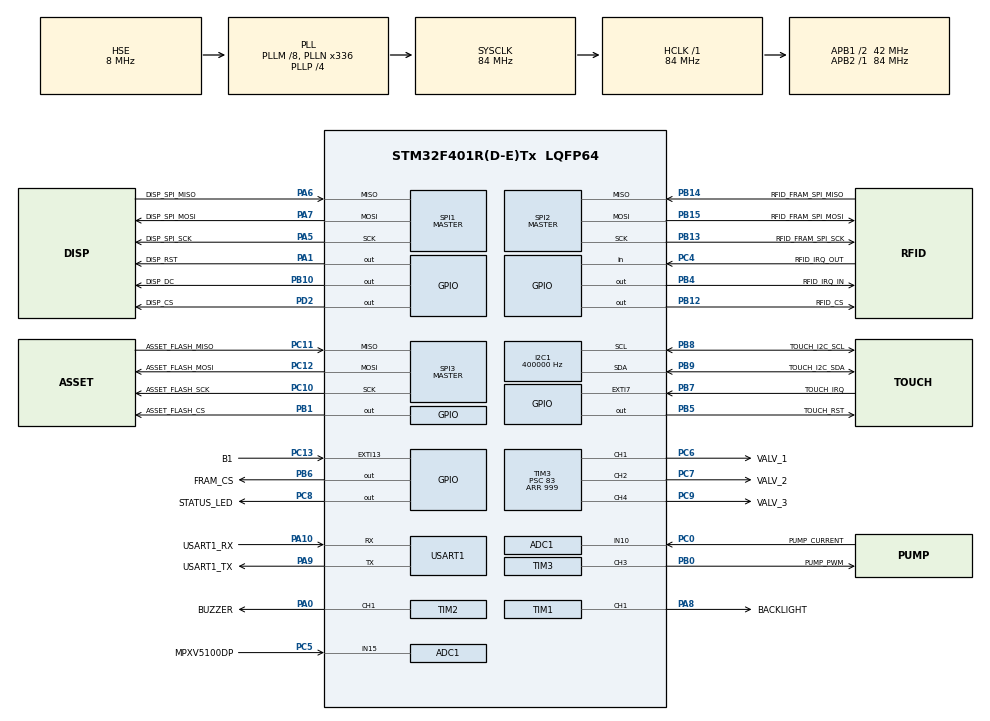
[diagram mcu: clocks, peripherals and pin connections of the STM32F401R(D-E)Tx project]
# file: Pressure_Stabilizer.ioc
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ADC1.Channel-0\#ChannelRegularConversion=ADC_CHANNEL_15
ADC1.Channel-1\#ChannelRegularConversion=ADC_CHANNEL_10
ADC1.NbrOfConversionFlag=2
ADC1.Rank-0\#ChannelRegularConversion=1
ADC1.Rank-1\#ChannelRegularConversion=2
ADC1.SamplingTime-0\#ChannelRegularConversion=ADC_SAMPLETIME_84CYCLES
ADC1.SamplingTime-1\#ChannelRegularConversion=ADC_SAMPLETIME_84CYCLES
ADC1.master=1
Dma.Request0=SPI1_TX
Dma.Request1=SPI3_RX
Dma.Request2=SPI3_TX
Dma.SPI1_TX.0.Direction=DMA_MEMORY_TO_PERIPH
Dma.SPI1_TX.0.FIFOMode=DMA_FIFOMODE_DISABLE
Dma.SPI1_TX.0.Instance=DMA2_Stream3
Dma.SPI1_TX.0.MemDataAlignment=DMA_MDATAALIGN_BYTE
Dma.SPI1_TX.0.MemInc=DMA_MINC_ENABLE
Dma.SPI1_TX.0.Mode=DMA_NORMAL
Dma.SPI1_TX.0.PeriphDataAlignment=DMA_PDATAALIGN_BYTE
Dma.SPI1_TX.0.PeriphInc=DMA_PINC_DISABLE
Dma.SPI1_TX.0.Priority=DMA_PRIORITY_HIGH
Dma.SPI3_RX.1.Direction=DMA_PERIPH_TO_MEMORY
Dma.SPI3_RX.1.FIFOMode=DMA_FIFOMODE_DISABLE
Dma.SPI3_RX.1.Instance=DMA1_Stream0
Dma.SPI3_RX.1.MemDataAlignment=DMA_MDATAALIGN_BYTE
Dma.SPI3_RX.1.MemInc=DMA_MINC_ENABLE
Dma.SPI3_RX.1.Mode=DMA_NORMAL
Dma.SPI3_RX.1.PeriphDataAlignment=DMA_PDATAALIGN_BYTE
Dma.SPI3_RX.1.PeriphInc=DMA_PINC_DISABLE
Dma.SPI3_RX.1.Priority=DMA_PRIORITY_HIGH
Dma.SPI3_TX.2.Direction=DMA_MEMORY_TO_PERIPH
Dma.SPI3_TX.2.FIFOMode=DMA_FIFOMODE_DISABLE
Dma.SPI3_TX.2.Instance=DMA1_Stream5
Dma.SPI3_TX.2.MemDataAlignment=DMA_MDATAALIGN_BYTE
Dma.SPI3_TX.2.MemInc=DMA_MINC_ENABLE
Dma.SPI3_TX.2.Mode=DMA_NORMAL
Dma.SPI3_TX.2.PeriphDataAlignment=DMA_PDATAALIGN_BYTE
Dma.SPI3_TX.2.PeriphInc=DMA_PINC_DISABLE
Dma.SPI3_TX.2.Priority=DMA_PRIORITY_HIGH
I2C1.ClockSpeed=400000
Mcu.Family=STM32F4
Mcu.Name=STM32F401R(D-E)Tx
Mcu.Package=LQFP64
NVIC.DMA1_Stream0_IRQn=true\:1\:0\:false\:false\:true\:true\:true\:true
NVIC.DMA1_Stream5_IRQn=true\:1\:0\:false\:false\:true\:true\:true\:true
NVIC.DMA2_Stream3_IRQn=true\:0\:0\:false\:false\:true\:true\:true\:true
NVIC.EXTI9_5_IRQn=true\:1\:0\:false\:false\:true\:true\:true\:true
NVIC.PriorityGroup=NVIC_PRIORITYGROUP_4
NVIC.TIM1_TRG_COM_TIM11_IRQn=true\:0\:0\:false\:false\:true\:true\:true\:true
NVIC.USART1_IRQn=true\:0\:0\:false\:false\:true\:true\:true\:true
PA0-WKUP.GPIO_Label=BUZZER
PA0-WKUP.Signal=S_TIM2_CH1_ETR
PA1.GPIO_Label=DISP_RST
PA1.Signal=GPIO_Output
PA10.GPIO_Label=USART1_RX
PA10.GPIO_Mode=GPIO_MODE_AF_PP
PA10.GPIO_PuPd=GPIO_NOPULL
PA10.GPIO_Speed=GPIO_SPEED_FREQ_VERY_HIGH
PA10.Mode=Asynchronous
PA10.Signal=USART1_RX
PA13.GPIO_Label=TMS
PA13.Mode=Serial_Wire
PA13.Signal=SYS_JTMS-SWDIO
PA14.GPIO_Label=TCK
PA14.Mode=Serial_Wire
PA14.Signal=SYS_JTCK-SWCLK
PA5.GPIO_Label=DISP_SPI_SCK
PA5.Mode=Full_Duplex_Master
PA5.Signal=SPI1_SCK
PA6.GPIO_Label=DISP_SPI_MISO
PA6.Mode=Full_Duplex_Master
PA6.Signal=SPI1_MISO
PA7.GPIO_Label=DISP_SPI_MOSI
PA7.Mode=Full_Duplex_Master
PA7.Signal=SPI1_MOSI
PA8.GPIO_Label=BACKLIGHT
PA8.Signal=S_TIM1_CH1
PA9.GPIO_Label=USART1_TX
PA9.GPIO_Mode=GPIO_MODE_AF_PP
PA9.GPIO_PuPd=GPIO_NOPULL
PA9.GPIO_Speed=GPIO_SPEED_FREQ_VERY_HIGH
PA9.Mode=Asynchronous
PA9.Signal=USART1_TX
PB0.GPIO_Label=PUMP_PWM
PB0.Signal=S_TIM3_CH3
PB1.GPIO_Label=ASSET_FLASH_CS
PB1.GPIO_Speed=GPIO_SPEED_FREQ_VERY_HIGH
PB1.PinState=GPIO_PIN_SET
PB1.Signal=GPIO_Output
PB10.GPIO_Label=DISP_DC
PB10.Signal=GPIO_Output
PB12.GPIO_Label=RFID_CS
PB12.Signal=GPIO_Output
PB13.GPIO_Label=RFID_FRAM_SPI_SCK
PB13.Mode=Full_Duplex_Master
PB13.Signal=SPI2_SCK
PB14.GPIO_Label=RFID_FRAM_SPI_MISO
PB14.Mode=Full_Duplex_Master
PB14.Signal=SPI2_MISO
PB15.GPIO_Label=RFID_FRAM_SPI_MOSI
PB15.Mode=Full_Duplex_Master
PB15.Signal=SPI2_MOSI
PB4.GPIO_Label=RFID_IRQ_IN
PB4.Signal=GPIO_Output
PB5.GPIO_Label=TOUCH_RST
PB5.Signal=GPIO_Output
PB6.GPIO_Label=FRAM_CS
PB6.Signal=GPIO_Output
PB7.GPIO_Label=TOUCH_IRQ
PB7.GPIO_ModeDefaultEXTI=GPIO_MODE_IT_FALLING
PB7.GPIO_PuPd=GPIO_PULLUP
PB7.Signal=GPXTI7
PB8.GPIO_Label=TOUCH_I2C_SCL
PB8.Mode=I2C
PB8.Signal=I2C1_SCL
PB9.GPIO_Label=TOUCH_I2C_SDA
PB9.Mode=I2C
PB9.Signal=I2C1_SDA
PC0.GPIO_Label=PUMP_CURRENT
PC0.Signal=ADCx_IN10
PC13-ANTI_TAMP.GPIO_Label=B1
PC13-ANTI_TAMP.GPIO_ModeDefaultEXTI=GPIO_MODE_IT_FALLING
PC13-ANTI_TAMP.GPIO_PuPd=GPIO_NOPULL
PC13-ANTI_TAMP.Signal=GPXTI13
PC14-OSC32_IN.Mode=LSE-External-Oscillator
PC14-OSC32_IN.Signal=RCC_OSC32_IN
PC15-OSC32_OUT.Mode=LSE-External-Oscillator
PC15-OSC32_OUT.Signal=RCC_OSC32_OUT
PC4.GPIO_Label=RFID_IRQ_OUT
PC4.Signal=GPIO_Input
PC5.GPIO_Label=MPXV5100DP
PC5.Signal=ADCx_IN15
PC6.GPIO_Label=VALV_1
PC6.Signal=S_TIM3_CH1
PC7.GPIO_Label=VALV_2
PC7.Signal=S_TIM3_CH2
PC8.GPIO_Label=STATUS_LED
PC8.Signal=GPIO_Output
PC9.GPIO_Label=VALV_3
PC9.Signal=S_TIM3_CH4
PC10.GPIO_Label=ASSET_FLASH_SCK
PC10.GPIO_Speed=GPIO_SPEED_FREQ_VERY_HIGH
PC10.Mode=Full_Duplex_Master
PC10.Signal=SPI3_SCK
PC11.GPIO_Label=ASSET_FLASH_MISO
PC11.GPIO_Speed=GPIO_SPEED_FREQ_VERY_HIGH
PC11.Mode=Full_Duplex_Master
PC11.Signal=SPI3_MISO
PC12.GPIO_Label=ASSET_FLASH_MOSI
PC12.GPIO_Speed=GPIO_SPEED_FREQ_VERY_HIGH
PC12.Mode=Full_Duplex_Master
PC12.Signal=SPI3_MOSI
PD2.GPIO_Label=DISP_CS
PD2.GPIO_Speed=GPIO_SPEED_FREQ_VERY_HIGH
PD2.Signal=GPIO_Output
PH0\ -\ OSC_IN.Mode=HSE-External-Clock-Source
PH0\ -\ OSC_IN.Signal=RCC_OSC_IN
PH1\ -\ OSC_OUT.Mode=HSE-External-Clock-Source
PH1\ -\ OSC_OUT.Signal=RCC_OSC_OUT
ProjectManager.HeapSize=0x200
ProjectManager.StackSize=0x400
ProjectManager.TargetToolchain=STM32CubeIDE
RCC.48MHZClocksFreq_Value=48000000
RCC.AHBFreq_Value=84000000
RCC.APB1CLKDivider=RCC_HCLK_DIV2
RCC.APB1Freq_Value=42000000
RCC.APB1TimFreq_Value=84000000
RCC.APB2Freq_Value=84000000
RCC.APB2TimFreq_Value=84000000
RCC.CortexFreq_Value=84000000
RCC.HCLKFreq_Value=84000000
RCC.HSE_VALUE=8000000
RCC.HSI_VALUE=16000000
RCC.LSE_VALUE=32768
RCC.PLLM=8
RCC.PLLN=336
RCC.PLLP=RCC_PLLP_DIV4
RCC.PLLQ=7
RCC.PLLSourceVirtual=RCC_PLLSOURCE_HSE
RCC.SYSCLKFreq_VALUE=84000000
RCC.SYSCLKSource=RCC_SYSCLKSOURCE_PLLCLK
RCC.VCOOutputFreq_Value=336000000
SH.ADCx_IN10.0=ADC1_IN10,IN10
SH.ADCx_IN15.0=ADC1_IN15,IN15
SH.S_TIM2_CH1_ETR.0=TIM2_CH1,PWM Generation1 CH1
SH.S_TIM1_CH1.0=TIM1_CH1,PWM Generation1 CH1
SH.S_TIM3_CH1.0=TIM3_CH1,PWM Generation1 CH1
SH.S_TIM3_CH2.0=TIM3_CH2,PWM Generation2 CH2
SH.S_TIM3_CH3.0=TIM3_CH3,PWM Generation3 CH3
SH.S_TIM3_CH4.0=TIM3_CH4,PWM Generation4 CH4
SPI1.BaudRatePrescaler=SPI_BAUDRATEPRESCALER_16
SPI1.CRCCalculation=SPI_CRCCALCULATION_DISABLE
SPI1.Direction=SPI_DIRECTION_2LINES
SPI1.Mode=SPI_MODE_MASTER
SPI1.VirtualType=VM_MASTER
SPI2.BaudRatePrescaler=SPI_BAUDRATEPRESCALER_32
SPI2.CRCCalculation=SPI_CRCCALCULATION_DISABLE
SPI2.Direction=SPI_DIRECTION_2LINES
SPI2.Mode=SPI_MODE_MASTER
SPI2.VirtualType=VM_MASTER
SPI3.BaudRatePrescaler=SPI_BAUDRATEPRESCALER_2
SPI3.CRCCalculation=SPI_CRCCALCULATION_DISABLE
SPI3.Direction=SPI_DIRECTION_2LINES
SPI3.Mode=SPI_MODE_MASTER
SPI3.VirtualType=VM_MASTER
STMicroelectronics.X-CUBE-TOUCHGFX.4.26.0.ApplicationCcGraphicsJjApplication=TouchGFXOoGenerator
STMicroelectronics.X-CUBE-TOUCHGFX.4.26.0.tgfx_block_size=6400
STMicroelectronics.X-CUBE-TOUCHGFX.4.26.0.tgfx_buffering_strategy=Partial
STMicroelectronics.X-CUBE-TOUCHGFX.4.26.0.tgfx_custom_height=480
STMicroelectronics.X-CUBE-TOUCHGFX.4.26.0.tgfx_custom_width=320
STMicroelectronics.X-CUBE-TOUCHGFX.4.26.0.tgfx_datareader=Enabled
STMicroelectronics.X-CUBE-TOUCHGFX.4.26.0.tgfx_datareader_dma_transfersize=250
STMicroelectronics.X-CUBE-TOUCHGFX.4.26.0.tgfx_datareader_mem_base_address=0x90000000
STMicroelectronics.X-CUBE-TOUCHGFX.4.26.0.tgfx_number_of_blocks=2
STMicroelectronics.X-CUBE-TOUCHGFX.4.26.0_IsPackSelfContextualization=true
TIM11.Period=165
TIM11.Prescaler=8399
TIM1.Channel-PWM\ Generation1\ CH1=TIM_CHANNEL_1
TIM1.Period=4199
TIM1.Prescaler=0
TIM1.Pulse-PWM\ Generation1\ CH1=4199
TIM2.AutoReloadPreload=TIM_AUTORELOAD_PRELOAD_ENABLE
TIM2.Channel-PWM\ Generation1\ CH1=TIM_CHANNEL_1
TIM2.Period=55999
TIM2.Prescaler=0
TIM2.Pulse-PWM\ Generation1\ CH1=27999
TIM3.Channel-PWM\ Generation1\ CH1=TIM_CHANNEL_1
TIM3.Channel-PWM\ Generation2\ CH2=TIM_CHANNEL_2
TIM3.Channel-PWM\ Generation3\ CH3=TIM_CHANNEL_3
TIM3.Channel-PWM\ Generation4\ CH4=TIM_CHANNEL_4
TIM3.Period=999
TIM3.Prescaler=83
TIM3.Pulse-PWM\ Generation1\ CH1=0
TIM3.Pulse-PWM\ Generation2\ CH2=0
TIM3.Pulse-PWM\ Generation3\ CH3=0
TIM3.Pulse-PWM\ Generation4\ CH4=0
USART1.VirtualMode=VM_ASYNC
VP_CRC_VS_CRC.Mode=CRC_Activate
VP_STMicroelectronics.X-CUBE-TOUCHGFX_VS_GraphicsJjApplication_4.26.0.Mode=GraphicsJjApplication
VP_TIM11_VS_ClockSourceINT.Mode=Enable_Timer
VP_TIM3_VS_ClockSourceINT.Mode=Internal
board=NUCLEO-F401RE

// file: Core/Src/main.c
/* USER CODE BEGIN Header */
/**
  ******************************************************************************
  * @file           : main.c
  * @brief          : Main program body
  ******************************************************************************
  * @attention
  *
  * Copyright (c) 2026 STMicroelectronics.
  * All rights reserved.
  *
  * This software is licensed under terms that can be found in the LICENSE file
  * in the root directory of this software component.
  * If no LICENSE file comes with this software, it is provided AS-IS.
  *
  ******************************************************************************
  */
/* USER CODE END Header */
#include "main.h"
#include "app_touchgfx.h"

/* USER CODE BEGIN Includes */
#include "RVA15MD_DisplayDriver.h"
#include "application_runtime.h"
#include "bandy_session_store.h"
#include "display_backlight.h"
#include "shared_spi2.h"
#include "w25q128jv.h"
/* USER CODE END Includes */

ADC_HandleTypeDef hadc1;

CRC_HandleTypeDef hcrc;

I2C_HandleTypeDef hi2c1;

SPI_HandleTypeDef hspi1;
SPI_HandleTypeDef hspi2;
SPI_HandleTypeDef hspi3;

TIM_HandleTypeDef htim1;
TIM_HandleTypeDef htim2;
TIM_HandleTypeDef htim3;
TIM_HandleTypeDef htim11;

UART_HandleTypeDef huart1;

DMA_HandleTypeDef hdma_spi1_tx;
DMA_HandleTypeDef hdma_spi3_rx;
DMA_HandleTypeDef hdma_spi3_tx;

void SystemClock_Config(void);
static void MX_GPIO_Init(void);
static void MX_ADC1_Init(void);
static void MX_CRC_Init(void);
static void MX_I2C1_Init(void);
static void MX_SPI1_Init(void);
static void MX_SPI2_Init(void);
static void MX_SPI3_Init(void);
static void MX_TIM1_Init(void);
static void MX_TIM3_Init(void);
static void MX_TIM11_Init(void);
static void MX_USART1_UART_Init(void);
static void MX_TIM2_Init(void);
static void MX_DMA_Init(void);

int main(void)
{

  /* MCU Configuration--------------------------------------------------------*/

  /* Reset of all peripherals, Initializes the Flash interface and the Systick. */
  HAL_Init();

  /* Configure the system clock */
  SystemClock_Config();

  /* Initialize all configured peripherals */
  MX_GPIO_Init();
  MX_DMA_Init();
  MX_ADC1_Init();
  MX_CRC_Init();
  MX_I2C1_Init();
  MX_SPI1_Init();
  MX_SPI2_Init();
  MX_SPI3_Init();
  MX_TIM1_Init();
  MX_TIM3_Init();
  MX_TIM11_Init();
  MX_USART1_UART_Init();
  MX_TIM2_Init();
  MX_TouchGFX_Init();
  /* USER CODE BEGIN 2 */
  SharedSpi2_Init();
  BandySessionStore_Init();
  DisplayBacklight_Init(&htim1, TIM_CHANNEL_1);
  DisplayDriver_DisplayReset();
  DisplayDriver_Init();
  DisplayDriver_DisplayInit();
  DisplayDriver_DisplayOn();
  App_init();
  HAL_TIM_Base_Start_IT(&htim11);
  /* USER CODE END 2 */

  /* Infinite loop */
  /* USER CODE BEGIN WHILE */
  while (1)
  {
    App_process();
    /* USER CODE END WHILE */

  MX_TouchGFX_Process();
  }
}

void SystemClock_Config(void)
{
  RCC_OscInitTypeDef RCC_OscInitStruct = {0};
  RCC_ClkInitTypeDef RCC_ClkInitStruct = {0};

  /** Configure the main internal regulator output voltage
  */
  __HAL_RCC_PWR_CLK_ENABLE();
  __HAL_PWR_VOLTAGESCALING_CONFIG(PWR_REGULATOR_VOLTAGE_SCALE2);

  /** Initializes the RCC Oscillators according to the specified parameters
  * in the RCC_OscInitTypeDef structure.
  */
  RCC_OscInitStruct.OscillatorType = RCC_OSCILLATORTYPE_HSE|RCC_OSCILLATORTYPE_LSE;
  RCC_OscInitStruct.HSEState = RCC_HSE_BYPASS;
  RCC_OscInitStruct.LSEState = RCC_LSE_ON;
  RCC_OscInitStruct.PLL.PLLState = RCC_PLL_ON;
  RCC_OscInitStruct.PLL.PLLSource = RCC_PLLSOURCE_HSE;
  RCC_OscInitStruct.PLL.PLLM = 8;
  RCC_OscInitStruct.PLL.PLLN = 336;
  RCC_OscInitStruct.PLL.PLLP = RCC_PLLP_DIV4;
  RCC_OscInitStruct.PLL.PLLQ = 7;
  if (HAL_RCC_OscConfig(&RCC_OscInitStruct) != HAL_OK)
  {
    Error_Handler();
  }

  /** Initializes the CPU, AHB and APB buses clocks
  */
  RCC_ClkInitStruct.ClockType = RCC_CLOCKTYPE_HCLK|RCC_CLOCKTYPE_SYSCLK
                              |RCC_CLOCKTYPE_PCLK1|RCC_CLOCKTYPE_PCLK2;
  RCC_ClkInitStruct.SYSCLKSource = RCC_SYSCLKSOURCE_PLLCLK;
  RCC_ClkInitStruct.AHBCLKDivider = RCC_SYSCLK_DIV1;
  RCC_ClkInitStruct.APB1CLKDivider = RCC_HCLK_DIV2;
  RCC_ClkInitStruct.APB2CLKDivider = RCC_HCLK_DIV1;

  if (HAL_RCC_ClockConfig(&RCC_ClkInitStruct, FLASH_LATENCY_2) != HAL_OK)
  {
    Error_Handler();
  }
}

static void MX_ADC1_Init(void)
{

  ADC_ChannelConfTypeDef sConfig = {0};

  /** Configure the global features of the ADC (Clock, Resolution, Data Alignment and number of conversion)
  */
  hadc1.Instance = ADC1;
  hadc1.Init.ClockPrescaler = ADC_CLOCK_SYNC_PCLK_DIV4;
  hadc1.Init.Resolution = ADC_RESOLUTION_12B;
  hadc1.Init.ScanConvMode = DISABLE;
  hadc1.Init.ContinuousConvMode = DISABLE;
  hadc1.Init.DiscontinuousConvMode = DISABLE;
  hadc1.Init.ExternalTrigConvEdge = ADC_EXTERNALTRIGCONVEDGE_NONE;
  hadc1.Init.ExternalTrigConv = ADC_SOFTWARE_START;
  hadc1.Init.DataAlign = ADC_DATAALIGN_RIGHT;
  hadc1.Init.NbrOfConversion = 1;
  hadc1.Init.DMAContinuousRequests = DISABLE;
  hadc1.Init.EOCSelection = ADC_EOC_SINGLE_CONV;
  if (HAL_ADC_Init(&hadc1) != HAL_OK)
  {
    Error_Handler();
  }

  /** Configure for the selected ADC regular channel its corresponding rank in the sequencer and its sample time.
  */
  sConfig.Channel = ADC_CHANNEL_15;
  sConfig.Rank = 1;
  sConfig.SamplingTime = ADC_SAMPLETIME_84CYCLES;
  if (HAL_ADC_ConfigChannel(&hadc1, &sConfig) != HAL_OK)
  {
    Error_Handler();
  }

  /** Configure for the selected ADC regular channel its corresponding rank in the sequencer and its sample time.
  */
  sConfig.Channel = ADC_CHANNEL_10;
  sConfig.Rank = 2;
  if (HAL_ADC_ConfigChannel(&hadc1, &sConfig) != HAL_OK)
  {
    Error_Handler();
  }

}

static void MX_CRC_Init(void)
{

  hcrc.Instance = CRC;
  if (HAL_CRC_Init(&hcrc) != HAL_OK)
  {
    Error_Handler();
  }

}

static void MX_I2C1_Init(void)
{

  hi2c1.Instance = I2C1;
  hi2c1.Init.ClockSpeed = 400000;
  hi2c1.Init.DutyCycle = I2C_DUTYCYCLE_2;
  hi2c1.Init.OwnAddress1 = 0;
  hi2c1.Init.AddressingMode = I2C_ADDRESSINGMODE_7BIT;
  hi2c1.Init.DualAddressMode = I2C_DUALADDRESS_DISABLE;
  hi2c1.Init.OwnAddress2 = 0;
  hi2c1.Init.GeneralCallMode = I2C_GENERALCALL_DISABLE;
  hi2c1.Init.NoStretchMode = I2C_NOSTRETCH_DISABLE;
  if (HAL_I2C_Init(&hi2c1) != HAL_OK)
  {
    Error_Handler();
  }

}

static void MX_SPI1_Init(void)
{

  hspi1.Instance = SPI1;
  hspi1.Init.Mode = SPI_MODE_MASTER;
  hspi1.Init.Direction = SPI_DIRECTION_2LINES;
  hspi1.Init.DataSize = SPI_DATASIZE_8BIT;
  hspi1.Init.CLKPolarity = SPI_POLARITY_LOW;
  hspi1.Init.CLKPhase = SPI_PHASE_1EDGE;
  hspi1.Init.NSS = SPI_NSS_SOFT;
  hspi1.Init.BaudRatePrescaler = SPI_BAUDRATEPRESCALER_16;
  hspi1.Init.FirstBit = SPI_FIRSTBIT_MSB;
  hspi1.Init.TIMode = SPI_TIMODE_DISABLE;
  hspi1.Init.CRCCalculation = SPI_CRCCALCULATION_DISABLE;
  hspi1.Init.CRCPolynomial = 10;
  if (HAL_SPI_Init(&hspi1) != HAL_OK)
  {
    Error_Handler();
  }

}

static void MX_SPI2_Init(void)
{

  hspi2.Instance = SPI2;
  hspi2.Init.Mode = SPI_MODE_MASTER;
  hspi2.Init.Direction = SPI_DIRECTION_2LINES;
  hspi2.Init.DataSize = SPI_DATASIZE_8BIT;
  hspi2.Init.CLKPolarity = SPI_POLARITY_LOW;
  hspi2.Init.CLKPhase = SPI_PHASE_1EDGE;
  hspi2.Init.NSS = SPI_NSS_SOFT;
  hspi2.Init.BaudRatePrescaler = SPI_BAUDRATEPRESCALER_32;
  hspi2.Init.FirstBit = SPI_FIRSTBIT_MSB;
  hspi2.Init.TIMode = SPI_TIMODE_DISABLE;
  hspi2.Init.CRCCalculation = SPI_CRCCALCULATION_DISABLE;
  hspi2.Init.CRCPolynomial = 10;
  if (HAL_SPI_Init(&hspi2) != HAL_OK)
  {
    Error_Handler();
  }

}

static void MX_SPI3_Init(void)
{

  hspi3.Instance = SPI3;
  hspi3.Init.Mode = SPI_MODE_MASTER;
  hspi3.Init.Direction = SPI_DIRECTION_2LINES;
  hspi3.Init.DataSize = SPI_DATASIZE_8BIT;
  hspi3.Init.CLKPolarity = SPI_POLARITY_LOW;
  hspi3.Init.CLKPhase = SPI_PHASE_1EDGE;
  hspi3.Init.NSS = SPI_NSS_SOFT;
  hspi3.Init.BaudRatePrescaler = SPI_BAUDRATEPRESCALER_2;
  hspi3.Init.FirstBit = SPI_FIRSTBIT_MSB;
  hspi3.Init.TIMode = SPI_TIMODE_DISABLE;
  hspi3.Init.CRCCalculation = SPI_CRCCALCULATION_DISABLE;
  hspi3.Init.CRCPolynomial = 10;
  if (HAL_SPI_Init(&hspi3) != HAL_OK)
  {
    Error_Handler();
  }

  /* USER CODE BEGIN SPI3_Init 2 */
  if (!W25Q128JV_Init())
  {
    Error_Handler();
  }
  if (!W25Q128JV_ValidateAssetPackage())
  {
    Error_Handler();
  }
  /* USER CODE END SPI3_Init 2 */
}

static void MX_TIM1_Init(void)
{
  TIM_MasterConfigTypeDef sMasterConfig = {0};
  TIM_OC_InitTypeDef sConfigOC = {0};

  htim1.Instance = TIM1;
  htim1.Init.Prescaler = 0;
  htim1.Init.CounterMode = TIM_COUNTERMODE_UP;
  htim1.Init.Period = 4199;
  htim1.Init.ClockDivision = TIM_CLOCKDIVISION_DIV1;
  htim1.Init.RepetitionCounter = 0;
  htim1.Init.AutoReloadPreload = TIM_AUTORELOAD_PRELOAD_DISABLE;
  if (HAL_TIM_PWM_Init(&htim1) != HAL_OK)
  {
    Error_Handler();
  }

  sMasterConfig.MasterOutputTrigger = TIM_TRGO_RESET;
  sMasterConfig.MasterSlaveMode = TIM_MASTERSLAVEMODE_DISABLE;
  if (HAL_TIMEx_MasterConfigSynchronization(&htim1, &sMasterConfig) != HAL_OK)
  {
    Error_Handler();
  }

  sConfigOC.OCMode = TIM_OCMODE_PWM1;
  sConfigOC.Pulse = 4199;
  sConfigOC.OCPolarity = TIM_OCPOLARITY_HIGH;
  sConfigOC.OCNPolarity = TIM_OCNPOLARITY_HIGH;
  sConfigOC.OCFastMode = TIM_OCFAST_DISABLE;
  sConfigOC.OCIdleState = TIM_OCIDLESTATE_RESET;
  sConfigOC.OCNIdleState = TIM_OCNIDLESTATE_RESET;
  if (HAL_TIM_PWM_ConfigChannel(&htim1, &sConfigOC, TIM_CHANNEL_1) != HAL_OK)
  {
    Error_Handler();
  }

  HAL_TIM_MspPostInit(&htim1);
}

static void MX_TIM2_Init(void)
{

  TIM_MasterConfigTypeDef sMasterConfig = {0};
  TIM_OC_InitTypeDef sConfigOC = {0};

  htim2.Instance = TIM2;
  htim2.Init.Prescaler = 0;
  htim2.Init.CounterMode = TIM_COUNTERMODE_UP;
  htim2.Init.Period = 55999;
  htim2.Init.ClockDivision = TIM_CLOCKDIVISION_DIV1;
  htim2.Init.AutoReloadPreload = TIM_AUTORELOAD_PRELOAD_ENABLE;
  if (HAL_TIM_PWM_Init(&htim2) != HAL_OK)
  {
    Error_Handler();
  }
  sMasterConfig.MasterOutputTrigger = TIM_TRGO_RESET;
  sMasterConfig.MasterSlaveMode = TIM_MASTERSLAVEMODE_DISABLE;
  if (HAL_TIMEx_MasterConfigSynchronization(&htim2, &sMasterConfig) != HAL_OK)
  {
    Error_Handler();
  }
  sConfigOC.OCMode = TIM_OCMODE_PWM1;
  sConfigOC.Pulse = 27999;
  sConfigOC.OCPolarity = TIM_OCPOLARITY_HIGH;
  sConfigOC.OCFastMode = TIM_OCFAST_DISABLE;
  if (HAL_TIM_PWM_ConfigChannel(&htim2, &sConfigOC, TIM_CHANNEL_1) != HAL_OK)
  {
    Error_Handler();
  }
  HAL_TIM_MspPostInit(&htim2);

}

static void MX_TIM3_Init(void)
{

  TIM_ClockConfigTypeDef sClockSourceConfig = {0};
  TIM_MasterConfigTypeDef sMasterConfig = {0};
  TIM_OC_InitTypeDef sConfigOC = {0};

  htim3.Instance = TIM3;
  htim3.Init.Prescaler = 83;
  htim3.Init.CounterMode = TIM_COUNTERMODE_UP;
  htim3.Init.Period = 999;
  htim3.Init.ClockDivision = TIM_CLOCKDIVISION_DIV1;
  htim3.Init.AutoReloadPreload = TIM_AUTORELOAD_PRELOAD_DISABLE;
  if (HAL_TIM_Base_Init(&htim3) != HAL_OK)
  {
    Error_Handler();
  }
  sClockSourceConfig.ClockSource = TIM_CLOCKSOURCE_INTERNAL;
  if (HAL_TIM_ConfigClockSource(&htim3, &sClockSourceConfig) != HAL_OK)
  {
    Error_Handler();
  }
  if (HAL_TIM_PWM_Init(&htim3) != HAL_OK)
  {
    Error_Handler();
  }
  sMasterConfig.MasterOutputTrigger = TIM_TRGO_RESET;
  sMasterConfig.MasterSlaveMode = TIM_MASTERSLAVEMODE_DISABLE;
  if (HAL_TIMEx_MasterConfigSynchronization(&htim3, &sMasterConfig) != HAL_OK)
  {
    Error_Handler();
  }
  sConfigOC.OCMode = TIM_OCMODE_PWM1;
  sConfigOC.Pulse = 0;
  sConfigOC.OCPolarity = TIM_OCPOLARITY_HIGH;
  sConfigOC.OCFastMode = TIM_OCFAST_DISABLE;
  if (HAL_TIM_PWM_ConfigChannel(&htim3, &sConfigOC, TIM_CHANNEL_1) != HAL_OK)
  {
    Error_Handler();
  }
  if (HAL_TIM_PWM_ConfigChannel(&htim3, &sConfigOC, TIM_CHANNEL_2) != HAL_OK)
  {
    Error_Handler();
  }
  if (HAL_TIM_PWM_ConfigChannel(&htim3, &sConfigOC, TIM_CHANNEL_3) != HAL_OK)
  {
    Error_Handler();
  }
  if (HAL_TIM_PWM_ConfigChannel(&htim3, &sConfigOC, TIM_CHANNEL_4) != HAL_OK)
  {
    Error_Handler();
  }
  HAL_TIM_MspPostInit(&htim3);

}

static void MX_TIM11_Init(void)
{

  htim11.Instance = TIM11;
  htim11.Init.Prescaler = 8399;
  htim11.Init.CounterMode = TIM_COUNTERMODE_UP;
  htim11.Init.Period = 165;
  htim11.Init.ClockDivision = TIM_CLOCKDIVISION_DIV1;
  htim11.Init.AutoReloadPreload = TIM_AUTORELOAD_PRELOAD_DISABLE;
  if (HAL_TIM_Base_Init(&htim11) != HAL_OK)
  {
    Error_Handler();
  }

}

static void MX_USART1_UART_Init(void)
{

  huart1.Instance = USART1;
  huart1.Init.BaudRate = 115200;
  huart1.Init.WordLength = UART_WORDLENGTH_8B;
  huart1.Init.StopBits = UART_STOPBITS_1;
  huart1.Init.Parity = UART_PARITY_NONE;
  huart1.Init.Mode = UART_MODE_TX_RX;
  huart1.Init.HwFlowCtl = UART_HWCONTROL_NONE;
  huart1.Init.OverSampling = UART_OVERSAMPLING_16;
  if (HAL_UART_Init(&huart1) != HAL_OK)
  {
    Error_Handler();
  }

}

static void MX_GPIO_Init(void)
{
  GPIO_InitTypeDef GPIO_InitStruct = {0};

  /* GPIO Ports Clock Enable */
  __HAL_RCC_GPIOC_CLK_ENABLE();
  __HAL_RCC_GPIOH_CLK_ENABLE();
  __HAL_RCC_GPIOA_CLK_ENABLE();
  __HAL_RCC_GPIOB_CLK_ENABLE();
  __HAL_RCC_GPIOD_CLK_ENABLE();

  /*Configure GPIO pin Output Level */
  HAL_GPIO_WritePin(GPIOA, DISP_RST_Pin|CAM_DISABLE_Pin, GPIO_PIN_RESET);

  /*Configure GPIO pin Output Level */
  HAL_GPIO_WritePin(GPIOB, DISP_DC_Pin|RFID_IRQ_IN_Pin|TOUCH_RST_Pin, GPIO_PIN_RESET);
  HAL_GPIO_WritePin(GPIOB, ASSET_FLASH_CS_Pin|RFID_CS_Pin|FRAM_CS_Pin, GPIO_PIN_SET);

  /*Configure GPIO pin Output Level */
  HAL_GPIO_WritePin(STATUS_LED_GPIO_Port, STATUS_LED_Pin, GPIO_PIN_RESET);

  /*Configure GPIO pin Output Level */
  HAL_GPIO_WritePin(DISP_CS_GPIO_Port, DISP_CS_Pin, GPIO_PIN_RESET);

  /*Configure GPIO pin : B1_Pin */
  GPIO_InitStruct.Pin = B1_Pin;
  GPIO_InitStruct.Mode = GPIO_MODE_IT_FALLING;
  GPIO_InitStruct.Pull = GPIO_NOPULL;
  HAL_GPIO_Init(B1_GPIO_Port, &GPIO_InitStruct);

  /*Configure GPIO pins : DISP_RST_Pin CAM_DISABLE_Pin */
  GPIO_InitStruct.Pin = DISP_RST_Pin|CAM_DISABLE_Pin;
  GPIO_InitStruct.Mode = GPIO_MODE_OUTPUT_PP;
  GPIO_InitStruct.Pull = GPIO_NOPULL;
  GPIO_InitStruct.Speed = GPIO_SPEED_FREQ_LOW;
  HAL_GPIO_Init(GPIOA, &GPIO_InitStruct);

  /*Configure GPIO pins : PA5 PA6 PA7 */
  GPIO_InitStruct.Pin = GPIO_PIN_5|GPIO_PIN_6|GPIO_PIN_7;
  GPIO_InitStruct.Mode = GPIO_MODE_AF_PP;
  GPIO_InitStruct.Pull = GPIO_NOPULL;
  GPIO_InitStruct.Speed = GPIO_SPEED_FREQ_VERY_HIGH;
  GPIO_InitStruct.Alternate = GPIO_AF5_SPI1;
  HAL_GPIO_Init(GPIOA, &GPIO_InitStruct);

  /*Configure GPIO pin : RFID_IRQ_OUT_Pin */
  GPIO_InitStruct.Pin = RFID_IRQ_OUT_Pin;
  GPIO_InitStruct.Mode = GPIO_MODE_INPUT;
  GPIO_InitStruct.Pull = GPIO_NOPULL;
  HAL_GPIO_Init(RFID_IRQ_OUT_GPIO_Port, &GPIO_InitStruct);

  /*Configure GPIO pins : ASSET_FLASH_CS_Pin DISP_DC_Pin RFID_CS_Pin
                           RFID_IRQ_IN_Pin TOUCH_RST_Pin FRAM_CS_Pin */
  GPIO_InitStruct.Pin = ASSET_FLASH_CS_Pin|DISP_DC_Pin|RFID_CS_Pin|RFID_IRQ_IN_Pin
                          |TOUCH_RST_Pin|FRAM_CS_Pin;
  GPIO_InitStruct.Mode = GPIO_MODE_OUTPUT_PP;
  GPIO_InitStruct.Pull = GPIO_NOPULL;
  GPIO_InitStruct.Speed = GPIO_SPEED_FREQ_LOW;
  HAL_GPIO_Init(GPIOB, &GPIO_InitStruct);

  /*Configure GPIO pins : PB13 PB14 PB15 */
  GPIO_InitStruct.Pin = GPIO_PIN_13|GPIO_PIN_14|GPIO_PIN_15;
  GPIO_InitStruct.Mode = GPIO_MODE_AF_PP;
  GPIO_InitStruct.Pull = GPIO_NOPULL;
  GPIO_InitStruct.Speed = GPIO_SPEED_FREQ_VERY_HIGH;
  GPIO_InitStruct.Alternate = GPIO_AF5_SPI2;
  HAL_GPIO_Init(GPIOB, &GPIO_InitStruct);

  /*Configure GPIO pins : PC10 PC11 PC12 */
  GPIO_InitStruct.Pin = GPIO_PIN_10|GPIO_PIN_11|GPIO_PIN_12;
  GPIO_InitStruct.Mode = GPIO_MODE_AF_PP;
  GPIO_InitStruct.Pull = GPIO_NOPULL;
  GPIO_InitStruct.Speed = GPIO_SPEED_FREQ_VERY_HIGH;
  GPIO_InitStruct.Alternate = GPIO_AF6_SPI3;
  HAL_GPIO_Init(GPIOC, &GPIO_InitStruct);

  /*Configure GPIO pin : STATUS_LED_Pin */
  GPIO_InitStruct.Pin = STATUS_LED_Pin;
  GPIO_InitStruct.Mode = GPIO_MODE_OUTPUT_PP;
  GPIO_InitStruct.Pull = GPIO_NOPULL;
  GPIO_InitStruct.Speed = GPIO_SPEED_FREQ_LOW;
  HAL_GPIO_Init(STATUS_LED_GPIO_Port, &GPIO_InitStruct);

  /*Configure GPIO pin : DISP_CS_Pin */
  GPIO_InitStruct.Pin = DISP_CS_Pin;
  GPIO_InitStruct.Mode = GPIO_MODE_OUTPUT_PP;
  GPIO_InitStruct.Pull = GPIO_NOPULL;
  GPIO_InitStruct.Speed = GPIO_SPEED_FREQ_VERY_HIGH;
  HAL_GPIO_Init(DISP_CS_GPIO_Port, &GPIO_InitStruct);

  /*Configure GPIO pin : TOUCH_IRQ_Pin */
  GPIO_InitStruct.Pin = TOUCH_IRQ_Pin;
  GPIO_InitStruct.Mode = GPIO_MODE_IT_FALLING;
  GPIO_InitStruct.Pull = GPIO_PULLUP;
  HAL_GPIO_Init(TOUCH_IRQ_GPIO_Port, &GPIO_InitStruct);

  /* EXTI interrupt init*/
  HAL_NVIC_SetPriority(EXTI9_5_IRQn, 1, 0);
  HAL_NVIC_EnableIRQ(EXTI9_5_IRQn);

}

static void MX_DMA_Init(void)
{
  __HAL_RCC_DMA1_CLK_ENABLE();
  __HAL_RCC_DMA2_CLK_ENABLE();

  HAL_NVIC_SetPriority(DMA1_Stream0_IRQn, 1, 0);
  HAL_NVIC_EnableIRQ(DMA1_Stream0_IRQn);

  HAL_NVIC_SetPriority(DMA1_Stream5_IRQn, 1, 0);
  HAL_NVIC_EnableIRQ(DMA1_Stream5_IRQn);

  HAL_NVIC_SetPriority(DMA2_Stream3_IRQn, 0, 0);
  HAL_NVIC_EnableIRQ(DMA2_Stream3_IRQn);
}

void Error_Handler(void)
{
  __disable_irq();
  while (1)
  {
  }
}
